# ESM0_CFG register map
Vendor: Texas Instruments
Peripheral module from a debugger description file (folder J7VCL).
Registers are 32-bit, access not given, reset 0x0 unless marked. A register's access mark holds for its fields unless they carry their own. Offsets are as the file gives them; lines under a group give offsets from that group; [hi:lo] are bit positions; {n}, {i} and the like mark numbered series; 'fields as' and 'values as' point back to an identical list; <NAME> marks a mode.

## ESM0_CFG
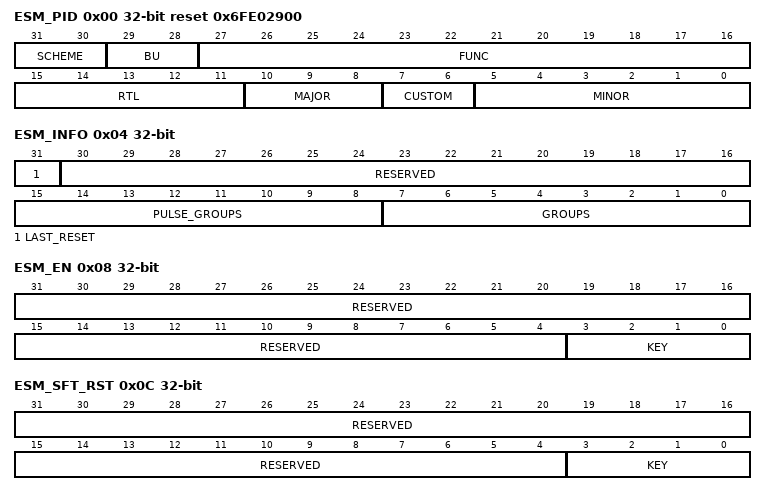
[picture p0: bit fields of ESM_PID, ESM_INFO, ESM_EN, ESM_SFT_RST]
0x00 ESM_PID ro reset 0x6FE02900 — The Revision Register contains the major and minor revisions for the module.
  [31:30] SCHEME — Always reads as 1h. Writes have no affect.
  [29:28] BU — Business Unit:2h = Processors
  [27:16] FUNC — Module ID. Always read as the assigned functional ID. Writes have no affect.
  [15:11] RTL — RTL revision.Will vary depending on release.
  [10:8] MAJOR — Major revision
  [7:6] CUSTOM — Custom. Special version.
  [5:0] MINOR — Minor revision
0x04 ESM_INFO ro (reset mask 0x80000000) — The Info Register gives the configuration information of this ESM.
  [31] LAST_RESET — This bit indicates whether the last reset was a Warm or Power-On Rest
  [30:16] RESERVED — Always read as 0h. Writes have no affect.
  [15:8] PULSE_GROUPS — Indicates the number of event groups that are pulse (as opposed to level) driven.
  [7:0] GROUPS — Indicates the total number of groups that exist in the ESM.
0x08 ESM_EN rw (reset mask 0xF) — The Global Enable Register has the master interrupt mask
  [31:4] RESERVED — Always read as 0h. Writes have no affect.
  [3:0] KEY — This field is the global mask for all interrupts. It is reset by the warm reset. The purpose is to leave all of the raw status and per-interrupt enable bits alone so that, after a warm reset, software may observe the state of the ESM before the warm reset and try to debug what may have caused the reset.
0x0C ESM_SFT_RST wo (reset mask 0xF) — The Global Soft Reset Register controls the global clear for raw status and enables
  [31:4] RESERVED — Always read as 0h. Writes have no affect.
  [3:0] KEY — Global Soft Reset field. Writing to this field can cause all of the raw status and all enables to be cleared. This can be used to reset the ESM state after debugging because of a warm reset.
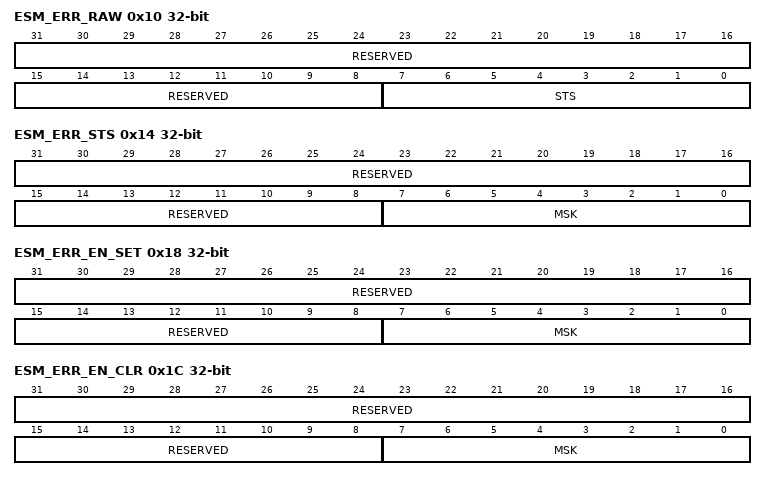
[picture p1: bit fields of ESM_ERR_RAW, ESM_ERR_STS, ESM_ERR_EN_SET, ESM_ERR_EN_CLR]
0x10 ESM_ERR_RAW (reset mask 0xFF) — Raw Status/Set Register for Configuration Errors
  [31:8] RESERVED rw — Always read as 0h. Writes have no affect.
  [7:0] STS — This is the raw status for errors in the configuration for Group N. This field is only reset by a Power-On-Reset (not warm reset). A global soft reset will set this field to 0h. (access RW1S)
0x14 ESM_ERR_STS (reset mask 0xFF) — Config Error Enable and Clear Register
  [31:8] RESERVED rw — Always read as 0h. Writes have no affect.
  [7:0] MSK — This is the masked status for errors in the configuration for Group N. This field is only reset by a Power-On-Reset (not warm reset). A global soft reset will set this field to 0. (access RW1C)
0x18 ESM_ERR_EN_SET (reset mask 0xFF) — Config Error Enable Set Register
  [31:8] RESERVED rw — Always read as 0h. Writes have no affect.
  [7:0] MSK — This is the mask enable for errors in the configuration for Group N. If the corresponding bit and the (access RW1S)
0x1C ESM_ERR_EN_CLR (reset mask 0xFF) — Config Error Interrupt Enabled Clear register
  [31:8] RESERVED rw — Always read as 0h. Writes have no affect.
  [7:0] MSK — This is the mask clear for errors in the configuration for Group N. If the corresponding bit and the (access RW1C)
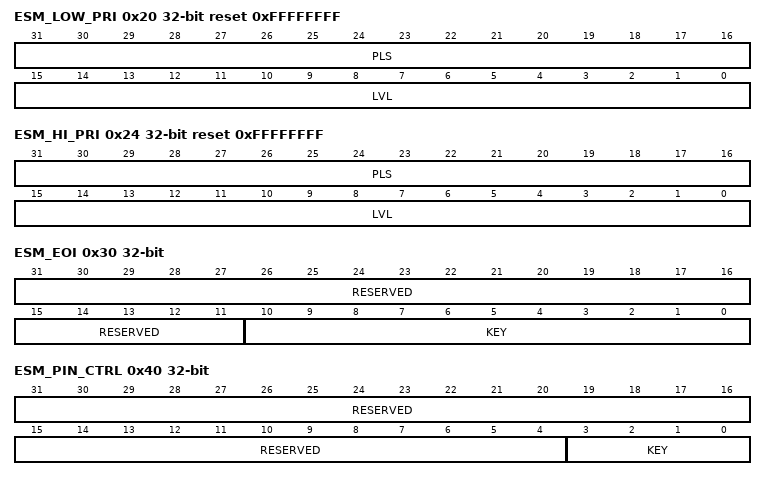
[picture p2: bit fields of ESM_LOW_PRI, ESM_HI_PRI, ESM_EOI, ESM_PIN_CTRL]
0x20 ESM_LOW_PRI ro reset 0xFFFFFFFF — Shows which is the highest priority outstanding low priority interrupt
  [31:16] PLS — Indicates what the highest priority low priority interrupt caused by a pulse number is. The lowest event has the highest priority. I.e. if Global Events 0, 1, 2, 3, and 4 are pending, and Global Event 0, and 1 are configured for high priority while Global Events 2, 3, and 4 are configured for low priority, then the value of this field will be 0x2. A value of all ones (0xFFFF) indicates that there are no low priority interrupts pending.
  [15:0] LVL — Indicates what the highest priority low priority interrupt caused by a level number is. The lowest event has the highest priority. I.e. if Global Events 0, 1, 2, 3, and 4 are pending, and Global Event 0, and 1 are configured for High Priority while Global Events 2, 3, and 4 are configured for low priority, then the value of this field will be 0x2. A value of all ones (0xFFFF) indicates that there are no low priority interrupts pending.
0x24 ESM_HI_PRI ro reset 0xFFFFFFFF — Shows which is the highest priority outstanding high priority interrupt
  [31:16] PLS — Indicates what the highest priority high priority interrupt caused by a pulse number is. The lowest event has the highest priority. I.e. if Global Events 0, 1, 2, 3, and 4 are pending, and Global Event 0, and 1 are configured for high priority while Global Events 2, 3, and 4 are configured for low priority, then the value of this field will be 0x0. A value of all ones (0xFFFF) indicates that there are no high priority interrupts pending.
  [15:0] LVL — Indicates what the highest priority low priority interrupt caused by a level number is. The lowest event has the highest priority. I.e. if Global Events 0, 1, 2, 3, and 4 are pending, and Global Event 0, and 1 are configured for high priority while Global Events 2, 3, and 4 are configured for low priority, then the value of this field will be 0x0. A value of all ones (0xFFFF) indicates that there are no high priority interrupts pending.
0x28 ESM_LOW ro — Shows which groups have outstanding low priority interrupts
  [31:0] STS — Indicates which Event Groups have one or more low priority interrupts pending. This register is bit oriented where bit 0 is for Event Group 0, bit 1 is for Event Group 1, etc… (bit N is for Event Group N).
0x2C ESM_HI ro — Shows which groups have outstanding high priority interrupts
  [31:0] STS — Indicates which Event Groups have one or more high priority interrupts pending. This register is bit oriented where bit 0 is for Event Group 0, bit 1 is for Event Group 1, etc… (bit N is for Event Group N).
0x30 ESM_EOI wo (reset mask 0x7FF) — End of Interrupt Register The EOI register is used to re-trigger the pulse interrupt signal to ensure that any nested interrupt events are serviced. The software interrupt handler must write to the EOI register at the end of the current interrupt processing routine, so that new events can re-trigger the pulse interrupt signal again. For level interrupt signals the EOI register is not functional and must not be used.
  [31:11] RESERVED — Always read as 0h. Writes have no affect.
  [10:0] KEY — This is the interrupt being serviced. Writing the corresponding vector to this field will cause a re-evaluation of interrupts. If, when the vector is written, there are still pending interrupts, a new pulse will be generated. Reads always return 0.
0x40 ESM_PIN_CTRL rw (reset mask 0xF) — This register controls the SAFETY_ERRORn pin output
  [31:4] RESERVED — Always read as 0h. Writes have no affect.
  [3:0] KEY — Pin control key. This field controls behavior of the error pin. Note, during reset the field is 0h, but the error pin is asserted (active low). Immediately after reset, the error pin de-asserts. This field is only reset by a Power-On-Reset (not warm reset). A global soft reset will set this field to 0. A global soft reset will also CLEAR all pending faults.
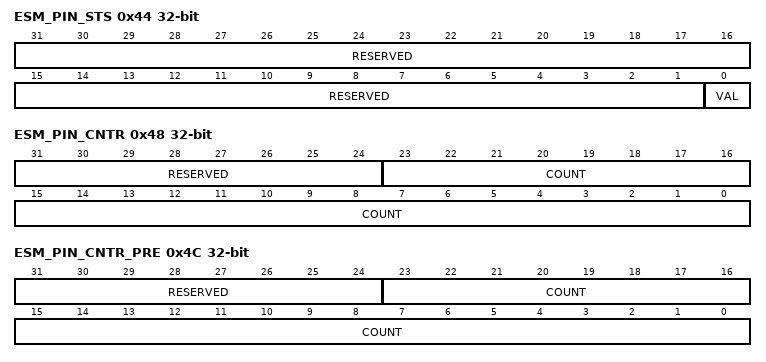
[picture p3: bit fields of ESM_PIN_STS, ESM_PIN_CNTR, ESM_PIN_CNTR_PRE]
0x44 ESM_PIN_STS ro reset not defined — This register reflects the status of the error_pin_n output
  [31:1] RESERVED — Always read as 0h. Writes have no affect.
  [0] VAL — This field indicates the status of the error pin as looped back from the I/O. This field reflects the state of the ERR_I pin. Since the ERR_O pin is only affected by Power-On-Reset, then the value of this field may be 1h after the release of Warm Reset.
0x48 ESM_PIN_CNTR ro (reset mask 0xFFFFFF) — This register shows the current value of the error pin counter
  [31:24] RESERVED — Always read as 0h. Writes have no affect.
  [23:0] COUNT — This field indicates the current value of the time interval counter. See
0x4C ESM_PIN_CNTR_PRE rw (reset mask 0xFFFFFF) — This register contains the value that is loaded in to the Error Counter
  [31:24] RESERVED — Always read as 0h. Writes have no affect.
  [23:0] COUNT — This is the value that will be pre-loaded in to the counter field of the
0x400 ESM_RAW_j — Raw Status/Set Register for Group A Errors Offset = 400h + (j * 20h); where j = 0h to 3h for WKUP_ESM0_CFG j = 0h to 3h for MCU_ESM0_CFG j = 0h to 7h for ESM0_CFG
  [31:0] STS — This is the raw status of the events in group N. Each bit corresponds to event Q where Q = N*32+Bit (Example: bit 0 is event N*32+0, bit 1 is N*32 + 1 etc…) (access RW1S)
0x404 ESM_STS_j — Error Enable and Clear Register Offset = 404h + (j * 20h); where j = 0h to 3h for WKUP_ESM0_CFG j = 0h to 3h for MCU_ESM0_CFG j = 0h to 7h for ESM0_CFG
  [31:0] MSK — This is the masked status of the events in group N. Each bit corresponds to event Q where Q = N*32+Bit (Example: bit 0 is event N*32+0, bit 1 is N*32 + 1 etc…) This field is only reset by a Power-On-Reset (not warm reset). A global soft reset will set this field to 0. (access RW1C)
0x408 ESM_INTR_EN_SET_j — Level Error Enable Set Register Offset = 408h + (j * 20h); where j = 0h to 3h for WKUP_ESM0_CFG j = 0h to 3h for MCU_ESM0_CFG j = 0h to 7h for ESM0_CFG
  [31:0] MSK — This field is used to enable the mask of events in group N. Each bit corresponds to event Q where Q = N*32+Bit (Example: bit 0 is event N*32+0, bit 1 is N*32 + 1 etc…) If the corresponding bit and the global enable (access RW1S)
0x40C ESM_INTR_EN_CLR_j — Level Error Interrupt Enabled Clear register Offset = 40Ch + (j * 20h); where j = 0h to 3h for WKUP_ESM0_CFG j = 0h to 3h for MCU_ESM0_CFG j = 0h to 7h for ESM0_CFG
  [31:0] MSK — This field is used to disable the mask of events in group N. Each bit corresponds to event Q where Q = N*32+Bit (Example: bit 0 is event N*32+0, bit 1 is N*32 + 1 etc…) If the corresponding bit and the global enable (access RW1C)
0x410 ESM_INT_PRIO_j rw — Level Error Interrupt Enabled Clear register Offset = 410h + (j * 20h); where j = 0h to 3h for WKUP_ESM0_CFG j = 0h to 3h for MCU_ESM0_CFG j = 0h to 7h for ESM0_CFG
  [31:0] MSK — This field is used to indicate which interrupt the corresponding event influences (if enabled) for event group N. Each bit corresponds to event Q where Q = N*32+Bit (Example: bit 0 is event N*32+0, bit 1 is N*32 + 1 etc…) This field is only reset by a Power-On-Reset (not warm reset). A global soft reset will set this field to 0.
0x414 ESM_PIN_EN_SET_j — Level Error Interrupt Enabled Clear register Offset = 414h + (j * 20h); where j = 0h to 3h for WKUP_ESM0_CFG j = 0h to 3h for MCU_ESM0_CFG j = 0h to 7h for ESM0_CFG
  [31:0] MSK — This field is used to enable the mask of events in group N. Each bit corresponds to event Q where Q = N*32+Bit (Example: bit 0 is event N*32+0, bit 1 is N*32 + 1 etc…) This field is only reset by a Power-On-Reset (not warm reset). A global soft reset will set this field to 0. (access RW1S)
0x418 ESM_PIN_EN_CLR_j — Level Error Interrupt Enabled Clear register Offset = 418h + (j * 20h); where j = 0h to 3h for WKUP_ESM0_CFG j = 0h to 3h for MCU_ESM0_CFG j = 0h to 7h for ESM0_CFG
  [31:0] MSK — This field is used to enable the mask of events in group N. Each bit corresponds to event Q where Q = N*32+Bit (Example: bit 0 is event N*32+0, bit 1 is N*32 + 1 etc…) This field is only reset by a Power-On-Reset (not warm reset). A global soft reset will set this field to 0. (access RW1C)
